# gpio_ctrl_model: IP-XACT component
VLNV IcronTechnologies:IcronTechnologies:gpio_ctrl_model:1.0

## Parameters
addr_width = 8
bus_width = 32

## Bus interfaces (logical=physical port)
default_map: slave AGNISYS:AGNISYS:APB:1.0, memory map gpio_ctrlmap
  pclk=pclk, presetn=presetn, psel=psel, penable=penable, pwrite=pwrite, pprot=pprot, pstrb=pstrb, pwdata=pwdata, paddr=paddr, pready=pready, prdata=prdata, pslverr=pslverr

## Ports
in pclk
in presetn
in psel
in penable
in pwrite
in pprot[2:0]
in pstrb[(bus_width div 8 )-1:0]
in pwdata[bus_width -1:0]
in paddr[addr_width -1:0]
out pready
out prdata[bus_width -1:0]
out pslverr

## Address spaces and blocks
gpio_ctrlmap.gpio_ctrl: base 0x000, range 0x100, width 32

## Registers
Registers are 32-bit, read-write, reset 0x0 unless marked. A register's access mark holds for its fields unless they carry their own. Offsets are from the block's base; lines under a group give offsets from that group; [hi:lo] are bit positions; {n}, {i} and the like mark numbered series; 'fields as' and 'values as' point back to an identical list; <NAME> marks a mode.

## gpio_ctrlmap.gpio_ctrl — GPIO Controller
Base 0x00000000
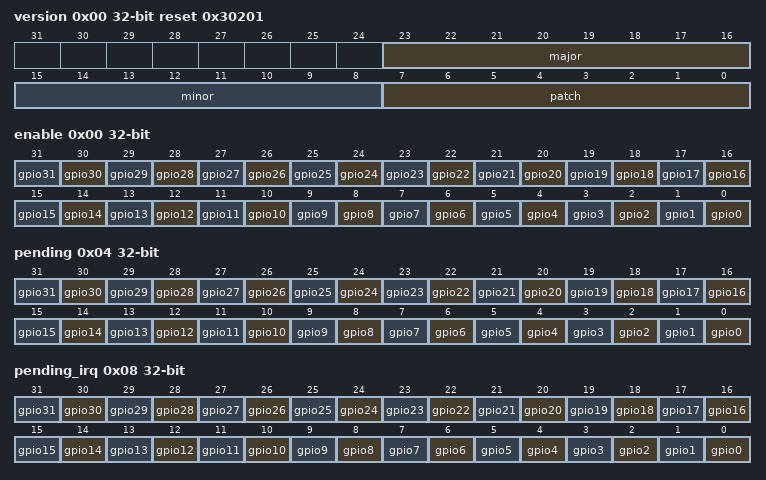
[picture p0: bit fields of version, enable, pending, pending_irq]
0x00 version ro reset 0x30201
  [23:16] major — Major version
  [15:8] minor — Minor version
  [7:0] patch — Patch version
0x04 gpio_dir — GPIO Direction
  [31:0] dir — GPIO Direction - one bit per GPIO 1'b0 : Input 1'b1 : Output
0x08 gpio_out — GPIO Output
  [31:0] out — GPIO Output - one bit per GPIO
0x0C gpio_in ro — GPIO Input
  [31:0] in — GPIO Input - one bit per GPIO
0x10 irq group — GPIO Controller Interrupt register group
  0x00 enable — Interrupt Enable register - Write 1 to enable, 0 to mask an interrupt
    [n] gpio{n} (n=0..31) — Interrupt enable for GPIO{n} input
  0x04 pending — Pending register - This indicates which GPIO inputs are pending, Write 1 to clear
    [n] gpio{n} write-1-clears (n=0..31) — Pending for GPIO{n} input
  0x08 pending_irq ro — Interrupt Pending register - This indicates which pending GPIO inputs are enabled to cause an interrupt
    [n] gpio{n} (n=0..31) — Interrupt pending for GPIO{n} input
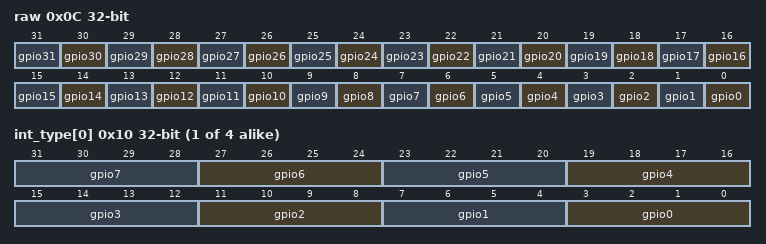
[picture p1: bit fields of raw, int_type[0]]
  0x0C raw ro — This register contains the registered state of interrupt signals
    [n] gpio{n} (n=0..31) — Current state for GPIO{n} input
  {0x10+4j} int_type[{j}] (j=0..3) — This register contains the interrupt type per GPIO
    [4n+3:4n] gpio{n} (n=0..7) — Interrupt Type 0 : Rising Edge 1 : Falling Edge 2 : Rising or Falling Edge 3 : High Level 4 : Low Level 5-15 : Reserved
